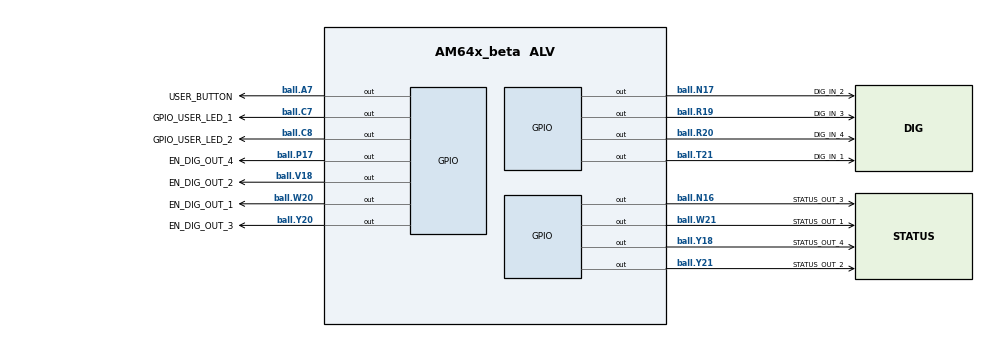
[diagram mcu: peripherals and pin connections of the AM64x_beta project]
/**
 * @cliArgs --device "AM64x_beta" --package "ALV" --part "Default" --context "r5fss0-0" --product "MCU_PLUS_SDK_AM64x@08.02.00"
 * @versions {"tool":"1.12.1+2446"}
 */

/**
 * Import the modules used in this configuration.
 */
const gpio       = scripting.addModule("/drivers/gpio/gpio", {}, false);
const gpio1      = gpio.addInstance();
const gpio2      = gpio.addInstance();
const gpio3      = gpio.addInstance();
const gpio4      = gpio.addInstance();
const gpio5      = gpio.addInstance();
const gpio6      = gpio.addInstance();
const gpio7      = gpio.addInstance();
const gpio8      = gpio.addInstance();
const gpio9      = gpio.addInstance();
const gpio10     = gpio.addInstance();
const gpio11     = gpio.addInstance();
const gpio12     = gpio.addInstance();
const gpio13     = gpio.addInstance();
const gpio14     = gpio.addInstance();
const gpio15     = gpio.addInstance();
const i2c        = scripting.addModule("/drivers/i2c/i2c", {}, false);
const i2c1       = i2c.addInstance();
const mcan       = scripting.addModule("/drivers/mcan/mcan", {}, false);
const mcan1      = mcan.addInstance();
const mcan2      = mcan.addInstance();
const mmcsd      = scripting.addModule("/drivers/mmcsd/mmcsd", {}, false);
const mmcsd1     = mmcsd.addInstance();
const ospi       = scripting.addModule("/drivers/ospi/ospi", {}, false);
const ospi1      = ospi.addInstance();
const uart       = scripting.addModule("/drivers/uart/uart", {}, false);
const uart1      = uart.addInstance();
const debug_log  = scripting.addModule("/kernel/dpl/debug_log");
const mpu_armv7  = scripting.addModule("/kernel/dpl/mpu_armv7", {}, false);
const mpu_armv71 = mpu_armv7.addInstance();
const mpu_armv72 = mpu_armv7.addInstance();
const mpu_armv73 = mpu_armv7.addInstance();
const mpu_armv74 = mpu_armv7.addInstance();
const mpu_armv75 = mpu_armv7.addInstance();
const mpu_armv76 = mpu_armv7.addInstance();

/**
 * Write custom configuration values to the imported modules.
 */
gpio1.pinDir                   = "OUTPUT";
gpio1.useMcuDomainPeripherals  = true;
gpio1.$name                    = "GPIO_USER_LED_1";
gpio1.MCU_GPIO.$assign         = "MCU_GPIO0";
gpio1.MCU_GPIO.gpioPin.$assign = "ball.C7";

gpio2.$name                    = "GPIO_USER_LED_2";
gpio2.pinDir                   = "OUTPUT";
gpio2.useMcuDomainPeripherals  = true;
gpio2.MCU_GPIO.gpioPin.$assign = "ball.C8";

gpio3.$name                = "DIG_IN_1";
gpio3.trigType             = "BOTH_EDGE";
gpio3.GPIO.gpioPin.$assign = "ball.T21";

gpio4.$name                = "DIG_IN_2";
gpio4.trigType             = "BOTH_EDGE";
gpio4.GPIO.gpioPin.$assign = "ball.N17";

gpio5.$name                = "DIG_IN_3";
gpio5.trigType             = "BOTH_EDGE";
gpio5.GPIO.gpioPin.$assign = "ball.R19";

gpio6.$name                = "DIG_IN_4";
gpio6.trigType             = "BOTH_EDGE";
gpio6.GPIO.gpioPin.$assign = "ball.R20";

gpio7.$name                = "EN_DIG_OUT_1";
gpio7.pinDir               = "OUTPUT";
gpio7.GPIO.gpioPin.$assign = "ball.W20";

gpio8.$name                = "STATUS_OUT_1";
gpio8.GPIO.gpioPin.$assign = "ball.W21";

gpio9.$name                = "EN_DIG_OUT_2";
gpio9.pinDir               = "OUTPUT";
gpio9.GPIO.gpioPin.$assign = "ball.V18";

gpio10.$name                = "STATUS_OUT_2";
gpio10.GPIO.gpioPin.$assign = "ball.Y21";

gpio11.$name                = "EN_DIG_OUT_3";
gpio11.pinDir               = "OUTPUT";
gpio11.GPIO.gpioPin.$assign = "ball.Y20";

gpio12.$name                = "STATUS_OUT_3";
gpio12.GPIO.gpioPin.$assign = "ball.N16";

gpio13.$name                = "EN_DIG_OUT_4";
gpio13.pinDir               = "OUTPUT";
gpio13.GPIO.gpioPin.$assign = "ball.P17";

gpio14.$name                = "STATUS_OUT_4";
gpio14.GPIO.gpioPin.$assign = "ball.Y18";

gpio15.$name                    = "USER_BUTTON";
gpio15.useMcuDomainPeripherals  = true;
gpio15.trigType                 = "RISE_EDGE";
gpio15.MCU_GPIO.gpioPin.$assign = "ball.A7";

i2c1.$name       = "CONFIG_I2C0";
i2c1.I2C.$assign = "I2C0";

mcan1.$name        = "CONFIG_MCAN0";
mcan1.MCAN.$assign = "MCAN0";

mcan2.$name        = "CONFIG_MCAN1";
mcan2.MCAN.$assign = "MCAN1";

mmcsd1.$name = "CONFIG_MMCSD0";

ospi1.$name        = "CONFIG_OSPI0";
ospi1.xferLines    = "QUAD";
ospi1.inputClkFreq = 83333333;

uart1.$name            = "CONFIG_USART0";
uart1.intrEnable       = "DISABLE";
uart1.UART.$assign     = "USART0";
uart1.UART.RXD.$assign = "ball.D15";
uart1.UART.TXD.$assign = "ball.C16";

mpu_armv71.$name             = "CONFIG_MPU_REGION0";
mpu_armv71.size              = 31;
mpu_armv71.attributes        = "Device";
mpu_armv71.accessPermissions = "Supervisor RD+WR, User RD";
mpu_armv71.allowExecute      = false;

mpu_armv72.$name             = "CONFIG_MPU_REGION1";
mpu_armv72.size              = 15;
mpu_armv72.accessPermissions = "Supervisor RD+WR, User RD";

mpu_armv73.$name             = "CONFIG_MPU_REGION2";
mpu_armv73.baseAddr          = 0x41010000;
mpu_armv73.size              = 15;
mpu_armv73.accessPermissions = "Supervisor RD+WR, User RD";

mpu_armv74.$name             = "CONFIG_MPU_REGION3";
mpu_armv74.baseAddr          = 0x70000000;
mpu_armv74.size              = 21;
mpu_armv74.accessPermissions = "Supervisor RD+WR, User RD";

mpu_armv75.$name             = "CONFIG_MPU_REGION4";
mpu_armv75.baseAddr          = 0x60000000;
mpu_armv75.size              = 28;
mpu_armv75.accessPermissions = "Supervisor RD, User RD";

mpu_armv76.$name    = "CONFIG_MPU_REGION5";
mpu_armv76.baseAddr = 0x80000000;
mpu_armv76.size     = 31;

/**
 * Pinmux solution for unlocked pins/peripherals. This ensures that minor changes to the automatic solver in a future
 * version of the tool will not impact the pinmux you originally saw.  These lines can be completely deleted in order to
 * re-solve from scratch.
 */
gpio2.MCU_GPIO.$suggestSolution  = "MCU_GPIO0";
gpio3.GPIO.$suggestSolution      = "GPIO0";
gpio4.GPIO.$suggestSolution      = "GPIO0";
gpio5.GPIO.$suggestSolution      = "GPIO0";
gpio6.GPIO.$suggestSolution      = "GPIO0";
gpio7.GPIO.$suggestSolution      = "GPIO0";
gpio8.GPIO.$suggestSolution      = "GPIO0";
gpio9.GPIO.$suggestSolution      = "GPIO0";
gpio10.GPIO.$suggestSolution     = "GPIO0";
gpio11.GPIO.$suggestSolution     = "GPIO0";
gpio12.GPIO.$suggestSolution     = "GPIO0";
gpio13.GPIO.$suggestSolution     = "GPIO0";
gpio14.GPIO.$suggestSolution     = "GPIO0";
gpio15.MCU_GPIO.$suggestSolution = "MCU_GPIO0";
i2c1.I2C.SCL.$suggestSolution    = "ball.A18";
i2c1.I2C.SDA.$suggestSolution    = "ball.B18";
mcan1.MCAN.RX.$suggestSolution   = "ball.B17";
mcan1.MCAN.TX.$suggestSolution   = "ball.A17";
mcan2.MCAN.RX.$suggestSolution   = "ball.D17";
mcan2.MCAN.TX.$suggestSolution   = "ball.C17";
mmcsd1.MMC0.$suggestSolution     = "MMC0";
ospi1.OSPI.$suggestSolution      = "OSPI0";
ospi1.OSPI.CLK.$suggestSolution  = "ball.N20";
ospi1.OSPI.CSn0.$suggestSolution = "ball.L19";
ospi1.OSPI.D3.$suggestSolution   = "ball.M21";
ospi1.OSPI.D2.$suggestSolution   = "ball.M20";
ospi1.OSPI.D1.$suggestSolution   = "ball.M18";
ospi1.OSPI.D0.$suggestSolution   = "ball.M19";
